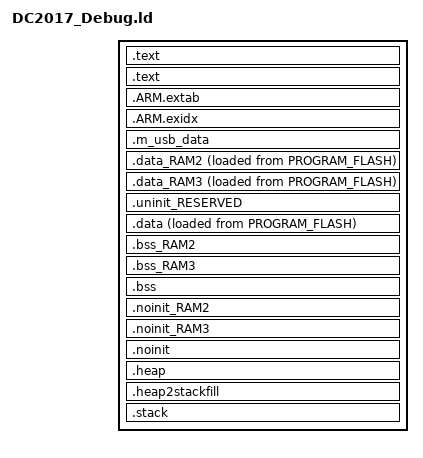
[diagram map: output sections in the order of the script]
/*
 * GENERATED FILE - DO NOT EDIT
 * (c) Code Red Technologies Ltd, 2008-2013
 * (c) NXP Semiconductors 2013-2017
 * Generated linker script file for MK63FN1M0xxx12
 * Created from linkscript.ldt by FMCreateLinkLibraries
 * Using Freemarker v2.3.23
 * MCUXpresso IDE v10.0.0 [Build 344] [2017-03-21]  on Jun 5, 2017 5:35:31 PM
 */

INCLUDE "DC2017_Debug_library.ld"
INCLUDE "DC2017_Debug_memory.ld"

ENTRY(ResetISR)

SECTIONS
{
    /* MAIN TEXT SECTION */
    .text : ALIGN(4)
    {
        FILL(0xff)
        __vectors_start__ = ABSOLUTE(.) ;
        KEEP(*(.isr_vector))
        /* Global Section Table */
        . = ALIGN(4) ;
        __section_table_start = .;
        __data_section_table = .;
        LONG(LOADADDR(.data));
        LONG(    ADDR(.data));
        LONG(  SIZEOF(.data));
        LONG(LOADADDR(.data_RAM2));
        LONG(    ADDR(.data_RAM2));
        LONG(  SIZEOF(.data_RAM2));
        LONG(LOADADDR(.data_RAM3));
        LONG(    ADDR(.data_RAM3));
        LONG(  SIZEOF(.data_RAM3));
        __data_section_table_end = .;
        __bss_section_table = .;
        LONG(    ADDR(.bss));
        LONG(  SIZEOF(.bss));
        LONG(    ADDR(.bss_RAM2));
        LONG(  SIZEOF(.bss_RAM2));
        LONG(    ADDR(.bss_RAM3));
        LONG(  SIZEOF(.bss_RAM3));
        __bss_section_table_end = .;
        __section_table_end = . ;
	    /* End of Global Section Table */

        *(.after_vectors*)


        /* Kinetis Flash Configuration data */
        . = 0x400 ;
        PROVIDE(__FLASH_CONFIG_START__ = .) ;
        KEEP(*(.FlashConfig))
        PROVIDE(__FLASH_CONFIG_END__ = .) ;
        ASSERT(!(__FLASH_CONFIG_START__ == __FLASH_CONFIG_END__), "Linker Flash Config Support Enabled, but no .FlashConfig section provided within application");
        /* End of Kinetis Flash Configuration data */
        

    } >PROGRAM_FLASH

    .text : ALIGN(4)
    {
        *(.text*)
        *(.rodata .rodata.* .constdata .constdata.*)
        . = ALIGN(4);
    } > PROGRAM_FLASH
    /*
     * for exception handling/unwind - some Newlib functions (in common
     * with C++ and STDC++) use this. 
     */
    .ARM.extab : ALIGN(4) 
    {
        *(.ARM.extab* .gnu.linkonce.armextab.*)
    } > PROGRAM_FLASH
    __exidx_start = .;

    .ARM.exidx : ALIGN(4)
    {
        *(.ARM.exidx* .gnu.linkonce.armexidx.*)
    } > PROGRAM_FLASH
    __exidx_end = .;

    _etext = .;
        
 
    /* USB_RAM */
    .m_usb_data (NOLOAD) :
    {
        *(m_usb_bdt)
    } > SRAM_UPPER
    /* DATA section for SRAM_LOWER */
    .data_RAM2 : ALIGN(4)
    {
        FILL(0xff)
        PROVIDE(__start_data_RAM2 = .) ;
        *(.ramfunc.$RAM2)
        *(.ramfunc.$SRAM_LOWER)
        *(.data.$RAM2*)
        *(.data.$SRAM_LOWER*)
        . = ALIGN(4) ;
        PROVIDE(__end_data_RAM2 = .) ;
     } > SRAM_LOWER AT>PROGRAM_FLASH

    /* DATA section for FLEX_RAM */
    .data_RAM3 : ALIGN(4)
    {
        FILL(0xff)
        PROVIDE(__start_data_RAM3 = .) ;
        *(.ramfunc.$RAM3)
        *(.ramfunc.$FLEX_RAM)
        *(.data.$RAM3*)
        *(.data.$FLEX_RAM*)
        . = ALIGN(4) ;
        PROVIDE(__end_data_RAM3 = .) ;
     } > FLEX_RAM AT>PROGRAM_FLASH

    /* MAIN DATA SECTION */
    .uninit_RESERVED : ALIGN(4)
    {
        KEEP(*(.bss.$RESERVED*))
        . = ALIGN(4) ;
        _end_uninit_RESERVED = .;
    } > SRAM_UPPER
    /* Main DATA section (SRAM_UPPER) */
    .data : ALIGN(4)
    {
       FILL(0xff)
       _data = . ;
       *(vtable)
       *(.ramfunc*)
       *(.data*)
       . = ALIGN(4) ;
       _edata = . ;
    } > SRAM_UPPER AT>PROGRAM_FLASH
    /* BSS section for SRAM_LOWER */
    .bss_RAM2 : ALIGN(4)
    {
       PROVIDE(__start_bss_RAM2 = .) ;
       *(.bss.$RAM2*)
       *(.bss.$SRAM_LOWER*)
       . = ALIGN (. != 0 ? 4 : 1) ; /* avoid empty segment */
       PROVIDE(__end_bss_RAM2 = .) ;
    } > SRAM_LOWER 
    /* BSS section for FLEX_RAM */
    .bss_RAM3 : ALIGN(4)
    {
       PROVIDE(__start_bss_RAM3 = .) ;
       *(.bss.$RAM3*)
       *(.bss.$FLEX_RAM*)
       . = ALIGN (. != 0 ? 4 : 1) ; /* avoid empty segment */
       PROVIDE(__end_bss_RAM3 = .) ;
    } > FLEX_RAM 
    /* MAIN BSS SECTION */
    .bss : ALIGN(4)
    {
        _bss = .;
        *(.bss*)
        *(COMMON)
        . = ALIGN(4) ;
        _ebss = .;
        PROVIDE(end = .);
    } > SRAM_UPPER
    /* NOINIT section for SRAM_LOWER */
    .noinit_RAM2 (NOLOAD) : ALIGN(4)
    {
       *(.noinit.$RAM2*)
       *(.noinit.$SRAM_LOWER*)
       . = ALIGN(4) ;
    } > SRAM_LOWER 
    /* NOINIT section for FLEX_RAM */
    .noinit_RAM3 (NOLOAD) : ALIGN(4)
    {
       *(.noinit.$RAM3*)
       *(.noinit.$FLEX_RAM*)
       . = ALIGN(4) ;
    } > FLEX_RAM 
    /* DEFAULT NOINIT SECTION */
    .noinit (NOLOAD): ALIGN(4)
    {
        _noinit = .;
        *(.noinit*) 
         . = ALIGN(4) ;
        _end_noinit = .;
    } > SRAM_UPPER
    .heap :  ALIGN(4)
    {
        _pvHeapStart = .;
        . += 0x1000;
		. = ALIGN(4);
		_pvHeapLimit = .;
    } > SRAM_UPPER
       .heap2stackfill  : 
	{
		. += 0x1000;
	} > SRAM_UPPER
	.stack ORIGIN(SRAM_UPPER) + LENGTH(SRAM_UPPER) - 0x1000 - 0:  ALIGN(4)
	{
		_vStackBase = .;
		. = ALIGN(4);
		_vStackTop = . + 0x1000;
	} > SRAM_UPPER
}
